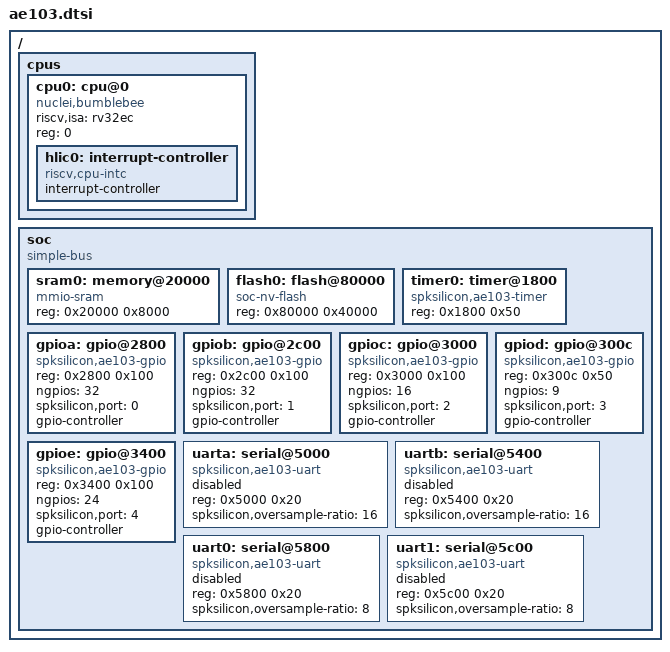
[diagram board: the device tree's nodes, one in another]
/*
 * Copyright (c) 2026 Sparkle Silicon Technology Corp., Ltd.
 * SPDX-License-Identifier: Apache-2.0
 */

/dts-v1/;

#include <zephyr/dt-bindings/dt-util.h>

/ {
	#address-cells = <1>;
	#size-cells = <1>;

	cpus {
		#address-cells = <1>;
		#size-cells = <0>;

		cpu0: cpu@0 {
			device_type = "cpu";
			compatible = "nuclei,bumblebee"; /* N100 蜂鸟核，binding 链声明 clock-frequency */
			riscv,isa = "rv32ec";
			reg = <0>;
			status = "okay";

			hlic0: interrupt-controller {
				compatible = "riscv,cpu-intc";
				#address-cells = <0>;
				#interrupt-cells = <1>;
				interrupt-controller;
			};
		};
	};

	soc {
		#address-cells = <1>;
		#size-cells = <1>;
		compatible = "simple-bus";
		ranges;

		/*
		 * SRAM (DLM): 0x20000, 32 KiB.
		 * TODO: peripheral register nodes (INTC0/INTC1, TIMER, UART, ...)
		 *       are added incrementally as their drivers land.
		 */
		sram0: memory@20000 {
			compatible = "mmio-sram";
			reg = <0x20000 0x8000>;
		};

		/* SPI flash XIP window: 0x80000, 256 KiB. */
		flash0: flash@80000 {
			compatible = "soc-nv-flash";
			reg = <0x80000 0x40000>;
		};

		/*
		 * SPK hardware timer: 4 x 16-bit down-counters @ 0x1800.
		 * 0x14 bytes per channel => 0x50 total.
		 */
		timer0: timer@1800 {
			compatible = "spksilicon,ae103-timer";
			reg = <0x1800 0x50>;
			status = "okay";
		};

		/*
		 * AE103 GPIO：5 个逻辑端口（GPIOA~E）→ 4 个物理基址。
		 * GPIOC(16) 与 GPIOD(9) 共享 0x3000，GPIOD 用高位寄存器
		 * （DR2@0x0C / DDR2@0x10 / EXT2@0x54），reg 指向 DR2 以区分
		 * unit-address。驱动经 spksilicon,port 查表取基址/偏移。
		 */
		gpioa: gpio@2800 {
			compatible = "spksilicon,ae103-gpio";
			reg = <0x2800 0x100>;
			ngpios = <32>;
			spksilicon,port = <0>;
			gpio-controller;
			#gpio-cells = <2>;
			status = "okay";
		};

		gpiob: gpio@2c00 {
			compatible = "spksilicon,ae103-gpio";
			reg = <0x2c00 0x100>;
			ngpios = <32>;
			spksilicon,port = <1>;
			gpio-controller;
			#gpio-cells = <2>;
			status = "okay";
		};

		gpioc: gpio@3000 {
			compatible = "spksilicon,ae103-gpio";
			reg = <0x3000 0x100>;
			ngpios = <16>;
			spksilicon,port = <2>;
			gpio-controller;
			#gpio-cells = <2>;
			status = "okay";
		};

		gpiod: gpio@300c {
			compatible = "spksilicon,ae103-gpio";
			reg = <0x300c 0x50>;
			ngpios = <9>;
			spksilicon,port = <3>;
			gpio-controller;
			#gpio-cells = <2>;
			status = "okay";
		};

		gpioe: gpio@3400 {
			compatible = "spksilicon,ae103-gpio";
			reg = <0x3400 0x100>;
			ngpios = <24>;
			spksilicon,port = <4>;
			gpio-controller;
			#gpio-cells = <2>;
			status = "okay";
		};

		/*
		 * AE103 UART: 16550-compatible, 4 ports（手册地址映射表 §4.1）。
		 *   UARTA/B  oversample 16x (16550 standard)
		 *   UART0/1  oversample 8x  (non-standard, low-power variant)
		 *
		 * 波特率时钟 f_uart 由主频经两级分频得出（ROM/KERNEL/KERNEL_UART.c
		 * UART_Init 通式）：
		 *   f_uart = CHIP_CLOCK_INT_HIGH / (SYSCTL_CLKDIV_OSC80M + 1)
		 *                                   / (SYSCTL_CLKDIV_UART  + 1)
		 * 默认：OSC80M 复位值 0x3（手册 5.11.41，即 80M/4）、UART 分频复位
		 * 值 0，故 f_uart = 80M/4/1 = 20 MHz（与 CPU 主频同频）。该频率不在
		 * DT 硬编码，由驱动经 clock.h 的
		 * ae103_clock_freq_get(AE103_CLOCK_DOMAIN_UART) 动态读取。
		 *
		 * console 默认挂 UART0，对齐裸机固件 debug 口。寄存器块 0x20
		 * 覆盖 0x00~0x1F（标准 16550 0x00~0x07 + AE103 扩展 USR@0x1F）。
		 */
		uarta: serial@5000 {
			compatible = "spksilicon,ae103-uart";
			reg = <0x5000 0x20>;
			spksilicon,oversample-ratio = <16>;
			status = "disabled";
		};

		uartb: serial@5400 {
			compatible = "spksilicon,ae103-uart";
			reg = <0x5400 0x20>;
			spksilicon,oversample-ratio = <16>;
			status = "disabled";
		};

		uart0: serial@5800 {
			compatible = "spksilicon,ae103-uart";
			reg = <0x5800 0x20>;
			spksilicon,oversample-ratio = <8>;
			status = "disabled";
		};

		uart1: serial@5c00 {
			compatible = "spksilicon,ae103-uart";
			reg = <0x5c00 0x20>;
			spksilicon,oversample-ratio = <8>;
			status = "disabled";
		};
	};
};
